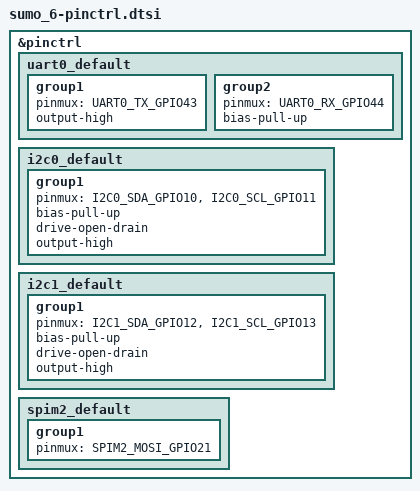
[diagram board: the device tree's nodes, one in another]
#include <zephyr/dt-bindings/pinctrl/esp-pinctrl-common.h>
#include <zephyr/dt-bindings/pinctrl/esp32s2-pinctrl.h>
#include <zephyr/dt-bindings/pinctrl/esp32s2-gpio-sigmap.h>

&pinctrl {
    uart0_default: uart0_default {
        group1 {
            pinmux = <UART0_TX_GPIO43>;
            output-high;
        };
        group2 {
            pinmux = <UART0_RX_GPIO44>;
            bias-pull-up;
        };
    };

    i2c0_default: i2c0_default {
        group1 {
            pinmux = <I2C0_SDA_GPIO10>,
                     <I2C0_SCL_GPIO11>;
            bias-pull-up;
            drive-open-drain;
            output-high;
        };
    };

    i2c1_default: i2c1_default {
        group1 {
            pinmux = <I2C1_SDA_GPIO12>,
                     <I2C1_SCL_GPIO13>;
            bias-pull-up;
            drive-open-drain;
            output-high;
        };
    };

    spim2_default: spim2_default {
        group1 {
            pinmux = <SPIM2_MOSI_GPIO21>;
        };
    };
};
